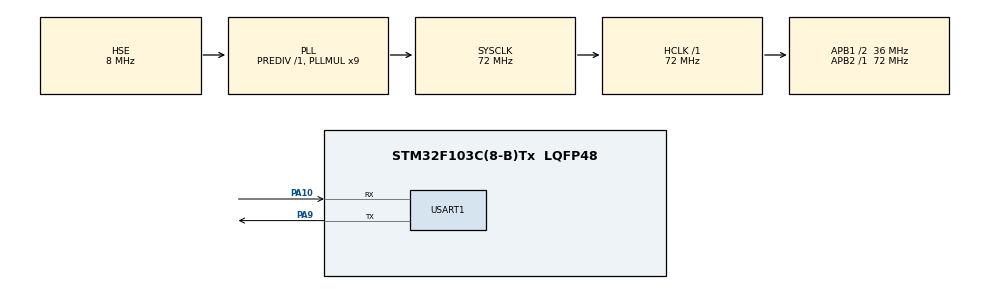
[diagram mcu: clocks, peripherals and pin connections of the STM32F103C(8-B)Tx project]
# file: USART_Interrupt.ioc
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Mcu.Family=STM32F1
Mcu.Name=STM32F103C(8-B)Tx
Mcu.Package=LQFP48
NVIC.PriorityGroup=NVIC_PRIORITYGROUP_4
NVIC.USART1_IRQn=true\:0\:0\:false\:false\:true\:true\:true\:true
PA10.Mode=Asynchronous
PA10.Signal=USART1_RX
PA13.Mode=Serial_Wire
PA13.Signal=SYS_JTMS-SWDIO
PA14.Mode=Serial_Wire
PA14.Signal=SYS_JTCK-SWCLK
PA9.Mode=Asynchronous
PA9.Signal=USART1_TX
PD0-OSC_IN.Mode=HSE-External-Oscillator
PD0-OSC_IN.Signal=RCC_OSC_IN
PD1-OSC_OUT.Mode=HSE-External-Oscillator
PD1-OSC_OUT.Signal=RCC_OSC_OUT
ProjectManager.HeapSize=0x200
ProjectManager.StackSize=0x400
ProjectManager.TargetToolchain=MDK-ARM V5.32
RCC.AHBFreq_Value=72000000
RCC.APB1CLKDivider=RCC_HCLK_DIV2
RCC.APB1Freq_Value=36000000
RCC.APB1TimFreq_Value=72000000
RCC.APB2Freq_Value=72000000
RCC.APB2TimFreq_Value=72000000
RCC.HCLKFreq_Value=72000000
RCC.PLLMUL=RCC_PLL_MUL9
RCC.PLLSourceVirtual=RCC_PLLSOURCE_HSE
RCC.SYSCLKFreq_VALUE=72000000
RCC.SYSCLKSource=RCC_SYSCLKSOURCE_PLLCLK
RCC.USBFreq_Value=72000000
USART1.VirtualMode=VM_ASYNC
board=custom

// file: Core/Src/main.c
/* USER CODE BEGIN Header */
/**
  ******************************************************************************
  * @file           : main.c
  * @brief          : Main program body
  ******************************************************************************
  * @attention
  *
  * Copyright (c) 2025 STMicroelectronics.
  * All rights reserved.
  *
  * This software is licensed under terms that can be found in the LICENSE file
  * in the root directory of this software component.
  * If no LICENSE file comes with this software, it is provided AS-IS.
  *
  ******************************************************************************
  */
/* USER CODE END Header */
#include "main.h"
#include "usart.h"
#include "gpio.h"

/* USER CODE BEGIN Includes */
#include <stdio.h>
#include <string.h>
/* USER CODE END Includes */

/* USER CODE BEGIN PV */
// 接收缓存数组（定�?6字节�?
uint8_t rcv_buf[6] = {0};
// 发�?�缓存数�?
uint8_t send_buf[64] = {0};
// 接收计数
uint8_t rcv_cnt = 0;
// 包头错误标志
uint8_t header_err = 0;
// 数据接收完成标志
uint8_t data_received = 0;
/* USER CODE END PV */

void SystemClock_Config(void);
/* USER CODE BEGIN PFP */
void USART1_SendReply(void);
void USART1_SendDebugInfo(void);
void HAL_UART_RxCpltCallback(UART_HandleTypeDef *huart);
/* USER CODE END PFP */

int main(void)
{

  /* MCU Configuration--------------------------------------------------------*/

  /* Reset of all peripherals, Initializes the Flash interface and the Systick. */
  HAL_Init();

  /* Configure the system clock */
  SystemClock_Config();

  /* Initialize all configured peripherals */
  MX_GPIO_Init();
  MX_USART1_UART_Init();
  /* USER CODE BEGIN 2 */
  // �?启USART1接收中断，接�?1个字�?
  HAL_UART_Receive_IT(&huart1, &rcv_buf[rcv_cnt], 1);
  /* USER CODE END 2 */

  /* Infinite loop */
  while (1)
  {

    // 检查是否接收到完整数据
    if(data_received == 1)
    {
      // 发送调试信息
      USART1_SendDebugInfo();

      // 发送回复
      USART1_SendReply();

      // 清除标志
      data_received = 0;
      header_err = 0;
      rcv_cnt = 0;

      // 清空接收缓存
      memset(rcv_buf, 0, sizeof(rcv_buf));

      // 重新开启接收中断
      HAL_UART_Receive_IT(&huart1, &rcv_buf[rcv_cnt], 1);
    }

  }
}

void SystemClock_Config(void)
{
  RCC_OscInitTypeDef RCC_OscInitStruct = {0};
  RCC_ClkInitTypeDef RCC_ClkInitStruct = {0};

  /** Initializes the RCC Oscillators according to the specified parameters
  * in the RCC_OscInitTypeDef structure.
  */
  RCC_OscInitStruct.OscillatorType = RCC_OSCILLATORTYPE_HSE;
  RCC_OscInitStruct.HSEState = RCC_HSE_ON;
  RCC_OscInitStruct.HSEPredivValue = RCC_HSE_PREDIV_DIV1;
  RCC_OscInitStruct.HSIState = RCC_HSI_ON;
  RCC_OscInitStruct.PLL.PLLState = RCC_PLL_ON;
  RCC_OscInitStruct.PLL.PLLSource = RCC_PLLSOURCE_HSE;
  RCC_OscInitStruct.PLL.PLLMUL = RCC_PLL_MUL9;
  if (HAL_RCC_OscConfig(&RCC_OscInitStruct) != HAL_OK)
  {
    Error_Handler();
  }

  /** Initializes the CPU, AHB and APB buses clocks
  */
  RCC_ClkInitStruct.ClockType = RCC_CLOCKTYPE_HCLK|RCC_CLOCKTYPE_SYSCLK
                              |RCC_CLOCKTYPE_PCLK1|RCC_CLOCKTYPE_PCLK2;
  RCC_ClkInitStruct.SYSCLKSource = RCC_SYSCLKSOURCE_PLLCLK;
  RCC_ClkInitStruct.AHBCLKDivider = RCC_SYSCLK_DIV1;
  RCC_ClkInitStruct.APB1CLKDivider = RCC_HCLK_DIV2;
  RCC_ClkInitStruct.APB2CLKDivider = RCC_HCLK_DIV1;

  if (HAL_RCC_ClockConfig(&RCC_ClkInitStruct, FLASH_LATENCY_2) != HAL_OK)
  {
    Error_Handler();
  }
}

/* USER CODE BEGIN 4 */

/**
  * @brief  发�?�回复函�?
  * @retval None
  */
void USART1_SendReply(void)
{
    uint16_t hour, minute;

    // 延时1�?
    HAL_Delay(1000);

    if(header_err == 0)
    {
        // 包头正确，转换时间并发�?�正常回�?
        hour = (uint16_t)rcv_buf[2];    // �?3字节：小时（16进制�?
        minute = (uint16_t)rcv_buf[3];  // �?4字节：分钟（16进制�?

        // 使用sprintf组字符串，格式：AB 时间 随便�?条信�? 换行
        sprintf((char*)send_buf, "AB %02d:%02d 要和我组乐队吗\r\n", hour, minute);
    }
    else
    {
        // 包头错误，发送错误信�?
        sprintf((char*)send_buf, "AB 包头错误\r\n");
    }

    // 发�?�字符串
    HAL_UART_Transmit(&huart1, send_buf, strlen((char*)send_buf), 1000);
}

/**
  * @brief  发�?�调试信息函�?
  * @retval None
  */
void USART1_SendDebugInfo(void)
{
    // �?化的调试信息
    sprintf((char*)send_buf, "DEBUG: ");
    HAL_UART_Transmit(&huart1, send_buf, strlen((char*)send_buf), 1000);

    // 发�?�每个字节的十六进制�?
    for(int i = 0; i < 6; i++)
    {
        sprintf((char*)send_buf, "%02X ", rcv_buf[i]);
        HAL_UART_Transmit(&huart1, send_buf, strlen((char*)send_buf), 1000);
    }

    // 发�?�包头检查结�?
    if(rcv_buf[0] == 0xAA && rcv_buf[1] == 0xBB)
    {
        sprintf((char*)send_buf, "OK\r\n");
    }
    else
    {
        sprintf((char*)send_buf, "ERROR\r\n");
    }
    HAL_UART_Transmit(&huart1, send_buf, strlen((char*)send_buf), 1000);
}

/**
  * @brief  UART接收完成回调函数
  * @param  huart: UART句柄
  * @retval None
  */
void HAL_UART_RxCpltCallback(UART_HandleTypeDef *huart)
{
    if(huart->Instance == USART1)
    {
        // 接收计数自增
        rcv_cnt++;

        // �?查是否接收完6字节数据
        if(rcv_cnt >= 6)
        {
            // �?查包头是否正�? (AA BB)
            if(rcv_buf[0] == 0xAA && rcv_buf[1] == 0xBB)
            {
                header_err = 0;  // 包头正确
            }
            else
            {
                header_err = 1;  // 包头错误
            }

            // 设置数据接收完成标志
            data_received = 1;
        }
        else
        {
            // 继续接收下一个字�?
            HAL_UART_Receive_IT(&huart1, &rcv_buf[rcv_cnt], 1);
        }
    }
}

/* USER CODE END 4 */

void Error_Handler(void)
{
  __disable_irq();
  while (1)
  {
  }
}
